AUTOSAR XML (schema 00046)
standard types defined: uint16, uint64, uint16_DataConstr, uint64_DataConstr
package /ComponentTypes
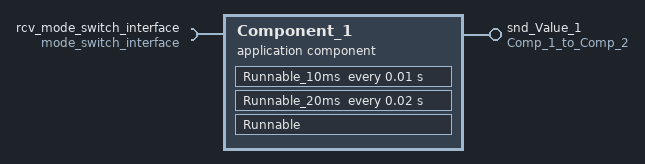
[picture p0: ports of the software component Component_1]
  application sw component type Component_1
    provide port snd_Value_1: nonqueued-sender-com-spec{data-element=InterRunnableVariable_Value_1, init-value=1}, provided-interface=Comp_1_to_Comp_2
    require port rcv_mode_switch_interface: mode-switch-receiver-com-spec{enhanced-mode-api=false, mode-group=Mode_switches, supports-asynchronous-mode-switch=false}, required-interface=mode_switch_interface
    behavior Component_1_InternalBehavior: handle-termination-and-restart=NO-SUPPORT
      swc mode switch event MST_Runnable_0: start-on-event=Runnable, activation=ON-TRANSITION, mode=[rcv_mode_switch_interface.Mode_switches.run, rcv_mode_switch_interface.Mode_switches.run]
      timing event TMT_Runnable_10ms: start-on-event=Runnable_10ms, period=0.01
      timing event TMT_Runnable_20ms: start-on-event=Runnable_20ms, period=0.02
      explicit-inter-runnable-variables:
        data InterRunnableVariable_Value_1: type=uint16, init-value=1
      runnable Runnable: mode-access-point=rcv_mode_switch_interface.Mode_switches
      runnable Runnable_10ms: can-be-invoked-concurrently=true
        written-local-variables:
          access WRITE_InterRunnableVariable: accessed-variable=InterRunnableVariable_Value_1
      runnable Runnable_20ms
        data-send-points:
          access SEND_snd_Value_1_Comp_1_value_1: accessed-variable=snd_Value_1.Comp_1_value_1
        read-local-variables:
          access Read_InterRunnableVariable: accessed-variable=InterRunnableVariable_Value_1
    symbol props Component_1: symbol=cs_Component_1
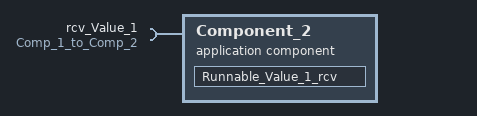
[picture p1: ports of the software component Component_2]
  application sw component type Component_2
    require port rcv_Value_1: nonqueued-receiver-com-spec{data-element=Comp_1_value_1, filter=data-filter-type=ALWAYS, init-value=1}, required-interface=Comp_1_to_Comp_2
    behavior Component_2_InternalBehavior: handle-termination-and-restart=NO-SUPPORT
      data received event DRT_Runnable_Value_1_rcv_rcv_Value_1_Comp_1_value_1: start-on-event=Runnable_Value_1_rcv, data=rcv_Value_1.Comp_1_value_1
      runnable Runnable_Value_1_rcv
        data-receive-point-by-arguments:
          access REC_rcv_Value_1_Comp_1_value_1: accessed-variable=rcv_Value_1.Comp_1_value_1
    symbol props Component_2: symbol=cs_Component_2
  composition sw component type ECU_1
    component Component_1: type=Component_1
    component Component_1_2: type=Component_1
    component Component_2: type=Component_2
    connect Component_1.snd_Value_1 -> Component_2.rcv_Value_1
  swc implementation Component_1_Implementation: behavior=Component_1_InternalBehavior
    code-descriptors:
      code Default: artifact-descriptors=autosar-engineering-object={short-label=Default, category=SWSRC}
  swc implementation Component_2_Implementation: behavior=Component_2_InternalBehavior
    code-descriptors:
      code Default: artifact-descriptors=autosar-engineering-object={short-label=Default, category=SWSRC}
package /ModeDclrGroups
  mode declaration group run_states: category=ALPHABETIC_ORDER, initial-mode=run
    mode run
    mode start
    mode terminate
package /PortInterfaces
  mode switch interface mode_switch_interface
    mode group Mode_switches: type=run_states
  sender receiver interface Comp_1_to_Comp_2: invalidation-policy{data-element=Comp_1_value_1, handle-invalid=DONT-INVALIDATE}
    data Comp_1_value_1: type=uint64
